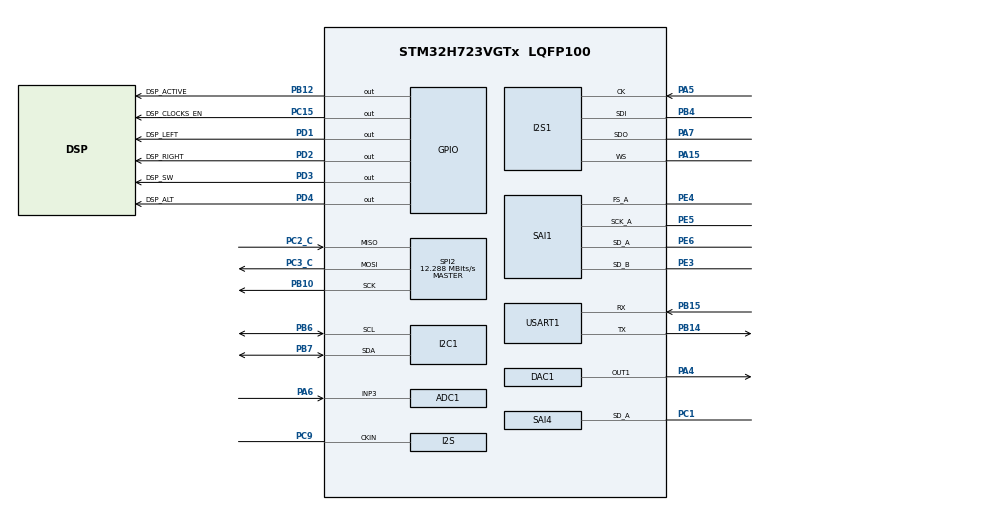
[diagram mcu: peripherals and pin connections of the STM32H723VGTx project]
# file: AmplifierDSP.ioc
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ADC1.Channel-1\#ChannelRegularConversion=ADC_CHANNEL_3
ADC1.NbrOfConversionFlag=1
ADC1.OffsetNumber-1\#ChannelRegularConversion=ADC_OFFSET_NONE
ADC1.OffsetSignedSaturation-1\#ChannelRegularConversion=DISABLE
ADC1.Rank-1\#ChannelRegularConversion=1
ADC1.SamplingTime-1\#ChannelRegularConversion=ADC_SAMPLETIME_1CYCLE_5
ADC1.master=1
Bdma.Request0=SAI4_A
Bdma.RequestsNb=1
Bdma.SAI4_A.0.Direction=DMA_MEMORY_TO_PERIPH
Bdma.SAI4_A.0.EventEnable=DISABLE
Bdma.SAI4_A.0.Instance=BDMA_Channel0
Bdma.SAI4_A.0.MemDataAlignment=DMA_MDATAALIGN_WORD
Bdma.SAI4_A.0.MemInc=DMA_MINC_ENABLE
Bdma.SAI4_A.0.Mode=DMA_NORMAL
Bdma.SAI4_A.0.PeriphDataAlignment=DMA_PDATAALIGN_WORD
Bdma.SAI4_A.0.PeriphInc=DMA_PINC_DISABLE
Bdma.SAI4_A.0.Polarity=HAL_DMAMUX_REQ_GEN_RISING
Bdma.SAI4_A.0.Priority=DMA_PRIORITY_VERY_HIGH
Bdma.SAI4_A.0.RequestNumber=1
Bdma.SAI4_A.0.SignalID=NONE
Bdma.SAI4_A.0.SyncEnable=DISABLE
Bdma.SAI4_A.0.SyncPolarity=HAL_DMAMUX_SYNC_NO_EVENT
Bdma.SAI4_A.0.SyncRequestNumber=1
Bdma.SAI4_A.0.SyncSignalID=NONE
CORTEX_M7.default_mode_Activation=1
DAC1.DAC_Channel-DAC_OUT1=DAC_CHANNEL_1
Dma.Request0=SPI1_RX
Dma.Request1=SPI1_TX
Dma.Request2=SAI1_A
Dma.Request3=SAI1_B
Dma.SAI1_A.2.Direction=DMA_MEMORY_TO_PERIPH
Dma.SAI1_A.2.EventEnable=DISABLE
Dma.SAI1_A.2.FIFOMode=DMA_FIFOMODE_DISABLE
Dma.SAI1_A.2.Instance=DMA1_Stream2
Dma.SAI1_A.2.MemDataAlignment=DMA_MDATAALIGN_WORD
Dma.SAI1_A.2.MemInc=DMA_MINC_ENABLE
Dma.SAI1_A.2.Mode=DMA_CIRCULAR
Dma.SAI1_A.2.PeriphDataAlignment=DMA_PDATAALIGN_WORD
Dma.SAI1_A.2.PeriphInc=DMA_PINC_DISABLE
Dma.SAI1_A.2.Polarity=HAL_DMAMUX_REQ_GEN_RISING
Dma.SAI1_A.2.Priority=DMA_PRIORITY_VERY_HIGH
Dma.SAI1_A.2.RequestNumber=1
Dma.SAI1_A.2.SignalID=NONE
Dma.SAI1_A.2.SyncEnable=DISABLE
Dma.SAI1_A.2.SyncPolarity=HAL_DMAMUX_SYNC_NO_EVENT
Dma.SAI1_A.2.SyncRequestNumber=1
Dma.SAI1_A.2.SyncSignalID=NONE
Dma.SAI1_B.3.Direction=DMA_MEMORY_TO_PERIPH
Dma.SAI1_B.3.EventEnable=DISABLE
Dma.SAI1_B.3.FIFOMode=DMA_FIFOMODE_DISABLE
Dma.SAI1_B.3.Instance=DMA1_Stream3
Dma.SAI1_B.3.MemDataAlignment=DMA_MDATAALIGN_WORD
Dma.SAI1_B.3.MemInc=DMA_MINC_ENABLE
Dma.SAI1_B.3.Mode=DMA_NORMAL
Dma.SAI1_B.3.PeriphDataAlignment=DMA_PDATAALIGN_WORD
Dma.SAI1_B.3.PeriphInc=DMA_PINC_DISABLE
Dma.SAI1_B.3.Polarity=HAL_DMAMUX_REQ_GEN_RISING
Dma.SAI1_B.3.Priority=DMA_PRIORITY_VERY_HIGH
Dma.SAI1_B.3.RequestNumber=1
Dma.SAI1_B.3.SignalID=NONE
Dma.SAI1_B.3.SyncEnable=DISABLE
Dma.SAI1_B.3.SyncPolarity=HAL_DMAMUX_SYNC_NO_EVENT
Dma.SAI1_B.3.SyncRequestNumber=1
Dma.SAI1_B.3.SyncSignalID=NONE
Dma.SPI1_RX.0.Direction=DMA_PERIPH_TO_MEMORY
Dma.SPI1_RX.0.EventEnable=DISABLE
Dma.SPI1_RX.0.FIFOMode=DMA_FIFOMODE_DISABLE
Dma.SPI1_RX.0.Instance=DMA1_Stream0
Dma.SPI1_RX.0.MemDataAlignment=DMA_MDATAALIGN_WORD
Dma.SPI1_RX.0.MemInc=DMA_MINC_ENABLE
Dma.SPI1_RX.0.Mode=DMA_CIRCULAR
Dma.SPI1_RX.0.PeriphDataAlignment=DMA_PDATAALIGN_WORD
Dma.SPI1_RX.0.PeriphInc=DMA_PINC_DISABLE
Dma.SPI1_RX.0.Polarity=HAL_DMAMUX_REQ_GEN_RISING
Dma.SPI1_RX.0.Priority=DMA_PRIORITY_VERY_HIGH
Dma.SPI1_RX.0.RequestNumber=1
Dma.SPI1_RX.0.SignalID=NONE
Dma.SPI1_RX.0.SyncEnable=DISABLE
Dma.SPI1_RX.0.SyncPolarity=HAL_DMAMUX_SYNC_NO_EVENT
Dma.SPI1_RX.0.SyncRequestNumber=1
Dma.SPI1_RX.0.SyncSignalID=NONE
Dma.SPI1_TX.1.Direction=DMA_MEMORY_TO_PERIPH
Dma.SPI1_TX.1.EventEnable=DISABLE
Dma.SPI1_TX.1.FIFOMode=DMA_FIFOMODE_DISABLE
Dma.SPI1_TX.1.Instance=DMA1_Stream1
Dma.SPI1_TX.1.MemDataAlignment=DMA_MDATAALIGN_WORD
Dma.SPI1_TX.1.MemInc=DMA_MINC_ENABLE
Dma.SPI1_TX.1.Mode=DMA_CIRCULAR
Dma.SPI1_TX.1.PeriphDataAlignment=DMA_PDATAALIGN_WORD
Dma.SPI1_TX.1.PeriphInc=DMA_PINC_DISABLE
Dma.SPI1_TX.1.Polarity=HAL_DMAMUX_REQ_GEN_RISING
Dma.SPI1_TX.1.Priority=DMA_PRIORITY_VERY_HIGH
Dma.SPI1_TX.1.RequestNumber=1
Dma.SPI1_TX.1.SignalID=NONE
Dma.SPI1_TX.1.SyncEnable=DISABLE
Dma.SPI1_TX.1.SyncPolarity=HAL_DMAMUX_SYNC_NO_EVENT
Dma.SPI1_TX.1.SyncRequestNumber=1
Dma.SPI1_TX.1.SyncSignalID=NONE
FREERTOS.Tasks01=mainThread,24,128,startMainThread,Default,NULL,Dynamic,NULL,NULL;audioThread,32,128,startAudioThread,Default,NULL,Dynamic,NULL,NULL
FREERTOS.configENABLE_FPU=1
FREERTOS.configUSE_NEWLIB_REENTRANT=1
I2C1.OwnAddress=50
I2C1.Timing=0x20A0A3F6
I2S1.AudioFreq=I2S_AUDIOFREQ_48K
I2S1.DataFormat=I2S_DATAFORMAT_24B
I2S1.ErrorAudioFreq=0.0 %
I2S1.Instance=SPI$Index
I2S1.RealAudioFreq=48.0 KHz
Mcu.Family=STM32H7
Mcu.Name=STM32H723VGTx
Mcu.Package=LQFP100
NVIC.BDMA_Channel0_IRQn=true\:5\:0\:false\:false\:true\:true\:false\:true\:true
NVIC.DMA1_Stream0_IRQn=true\:5\:0\:false\:false\:true\:true\:false\:true\:true
NVIC.DMA1_Stream1_IRQn=true\:5\:0\:false\:false\:true\:true\:false\:true\:true
NVIC.DMA1_Stream2_IRQn=true\:5\:0\:false\:false\:true\:true\:false\:true\:true
NVIC.DMA1_Stream3_IRQn=true\:5\:0\:false\:false\:true\:true\:false\:true\:true
NVIC.I2C1_ER_IRQn=true\:5\:0\:false\:false\:true\:true\:true\:true\:true
NVIC.I2C1_EV_IRQn=true\:5\:0\:false\:false\:true\:true\:true\:true\:true
NVIC.PriorityGroup=NVIC_PRIORITYGROUP_4
PA13(JTMS/SWDIO).Mode=Trace_Asynchronous_SW
PA13(JTMS/SWDIO).Signal=DEBUG_JTMS-SWDIO
PA14(JTCK/SWCLK).Mode=Trace_Asynchronous_SW
PA14(JTCK/SWCLK).Signal=DEBUG_JTCK-SWCLK
PA15(JTDI).Mode=Full_Duplex_Slave
PA15(JTDI).Signal=I2S1_WS
PA4.Signal=COMP_DAC11_group
PA5.Mode=Full_Duplex_Slave
PA5.Signal=I2S1_CK
PA6.Signal=ADCx_INP3
PA7.Mode=Full_Duplex_Slave
PA7.Signal=I2S1_SDO
PB10.Mode=Full_Duplex_Master
PB10.Signal=SPI2_SCK
PB12.GPIO_Label=DSP_ACTIVE
PB12.GPIO_PuPd=GPIO_PULLDOWN
PB12.Signal=GPIO_Output
PB14.Mode=Asynchronous
PB14.Signal=USART1_TX
PB15.Mode=Asynchronous
PB15.Signal=USART1_RX
PB3(JTDO/TRACESWO).Mode=Trace_Asynchronous_SW
PB3(JTDO/TRACESWO).Signal=DEBUG_JTDO-SWO
PB4(NJTRST).Mode=Full_Duplex_Slave
PB4(NJTRST).Signal=I2S1_SDI
PB6.Mode=I2C
PB6.Signal=I2C1_SCL
PB7.Mode=I2C
PB7.Signal=I2C1_SDA
PC1.Mode=SAI_A_SyncSlave
PC1.Signal=SAI4_SD_A
PC15-OSC32_OUT.GPIO_Label=DSP_CLOCKS_EN
PC15-OSC32_OUT.GPIO_PuPd=GPIO_PULLDOWN
PC15-OSC32_OUT.Signal=GPIO_Output
PC2_C.Mode=Full_Duplex_Master
PC2_C.Signal=SPI2_MISO
PC3_C.Mode=Full_Duplex_Master
PC3_C.Signal=SPI2_MOSI
PC9.Mode=Audio_ClockIn
PC9.Signal=I2S_CKIN
PD1.GPIO_Label=DSP_LEFT
PD1.GPIO_PuPd=GPIO_PULLDOWN
PD1.Signal=GPIO_Output
PD2.GPIO_Label=DSP_RIGHT
PD2.GPIO_PuPd=GPIO_PULLDOWN
PD2.Signal=GPIO_Output
PD3.GPIO_Label=DSP_SW
PD3.GPIO_PuPd=GPIO_PULLDOWN
PD3.Signal=GPIO_Output
PD4.GPIO_Label=DSP_ALT
PD4.GPIO_PuPd=GPIO_PULLDOWN
PD4.Signal=GPIO_Output
PE3.Mode=SAI_B_SyncSlave
PE3.Signal=SAI1_SD_B
PE4.Mode=SAI_A_AsyncSlave
PE4.Signal=SAI1_FS_A
PE5.Mode=SAI_A_AsyncSlave
PE5.Signal=SAI1_SCK_A
PE6.Mode=SAI_A_AsyncSlave
PE6.Signal=SAI1_SD_A
ProjectManager.HeapSize=0x200
ProjectManager.StackSize=0x400
ProjectManager.TargetToolchain=STM32CubeIDE
RCC.ADCFreq_Value=129000000
RCC.APB1Freq_Value=125000000
RCC.APB2Freq_Value=125000000
RCC.APB3Freq_Value=125000000
RCC.APB4Freq_Value=125000000
RCC.CortexFreq_Value=500000000
RCC.D1PPRE=RCC_APB3_DIV2
RCC.D2PPRE1=RCC_APB1_DIV2
RCC.D2PPRE2=RCC_APB2_DIV2
RCC.D3PPRE=RCC_APB4_DIV2
RCC.DIVM1=4
RCC.DIVN1=31
RCC.DIVP1=1
RCC.DIVQ1=4
RCC.EXTERNAL_CLOCK_VALUE=24576000
RCC.HCLKFreq_Value=250000000
RCC.HPRE=RCC_HCLK_DIV2
RCC.PLL2FRACN=0
RCC.PLL3FRACN=0
RCC.PLLFRACN=2048
RCC.SAI1CLockSelection=RCC_SAI1CLKSOURCE_PIN
RCC.SAI4ACLockSelection=RCC_SAI4ACLKSOURCE_PIN
RCC.SAI4BCLockSelection=RCC_SAI4BCLKSOURCE_PIN
RCC.SPI123CLockSelection=RCC_SPI123CLKSOURCE_PIN
RCC.SYSCLKFreq_VALUE=500000000
RCC.SYSCLKSource=RCC_SYSCLKSOURCE_PLLCLK
RCC.USBFreq_Value=125000000
SAI1.AudioMode-SAI_A_AsyncSlave=SAI_MODESLAVE_TX
SAI1.AudioMode-SAI_B_SyncSlave=SAI_MODESLAVE_TX
SAI1.BasicDataSize-SAI_A_AsyncSlave=SAI_PROTOCOL_DATASIZE_24BIT
SAI1.BasicDataSize-SAI_B_SyncSlave=SAI_PROTOCOL_DATASIZE_24BIT
SAI1.InitProtocol-SAI_A_AsyncSlave=Enable
SAI1.InitProtocol-SAI_B_SyncSlave=Enable
SAI1.Instance-SAI_A_AsyncSlave=SAI$Index_Block_A
SAI1.Instance-SAI_B_SyncSlave=SAI$Index_Block_B
SAI1.VirtualMode-SAI_A_AsyncSlave=VM_SLAVE
SAI1.VirtualMode-SAI_B_SyncSlave=VM_SLAVE
SAI1.VirtualProtocol-SAI_A_BASIC=VM_BASIC_PROTOCOL
SAI1.VirtualProtocol-SAI_B_BASIC=VM_BASIC_PROTOCOL
SAI4.AudioMode-SAI_A_SyncSlave=SAI_MODESLAVE_TX
SAI4.BasicDataSize-SAI_A_SyncSlave=SAI_PROTOCOL_DATASIZE_24BIT
SAI4.InitProtocol-SAI_A_SyncSlave=Enable
SAI4.Instance-SAI_A_SyncSlave=SAI$Index_Block_A
SAI4.VirtualMode-SAI_A_SyncSlave=VM_SLAVE
SAI4.VirtualProtocol-SAI_A_BASIC=VM_BASIC_PROTOCOL
SH.ADCx_INP3.0=ADC1_INP3,IN3-Single-Ended
SH.COMP_DAC11_group.0=DAC1_OUT1,DAC_OUT1
SPI2.CalculateBaudRate=12.288 MBits/s
SPI2.Direction=SPI_DIRECTION_2LINES
SPI2.Mode=SPI_MODE_MASTER
SPI2.VirtualType=VM_MASTER
USART1.VirtualMode-Asynchronous=VM_ASYNC
VP_FREERTOS_VS_CMSIS_V2.Mode=CMSIS_V2
VP_MEMORYMAP_VS_MEMORYMAP.Mode=CurAppReg
VP_SAI1_VP_$IpInstance_SAIA_SAI_BASIC.Mode=SAI_A_BASIC
VP_SAI1_VP_$IpInstance_SAIB_SAI_BASIC.Mode=SAI_B_BASIC
VP_SAI4_VP_$IpInstance_SAIA_SAI_BASIC.Mode=SAI_A_BASIC
board=custom

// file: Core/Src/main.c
/* USER CODE BEGIN Header */
/**
  ******************************************************************************
  * @file           : main.c
  * @brief          : Main program body
  ******************************************************************************
  * @attention
  *
  * Copyright (c) 2024 STMicroelectronics.
  * All rights reserved.
  *
  * This software is licensed under terms that can be found in the LICENSE file
  * in the root directory of this software component.
  * If no LICENSE file comes with this software, it is provided AS-IS.
  *
  ******************************************************************************
  */
/* USER CODE END Header */
#include "main.h"
#include "cmsis_os.h"

/* USER CODE BEGIN Includes */

#include <stdlib.h>
#include "arm_math.h"

/* USER CODE END Includes */

ADC_HandleTypeDef hadc1;

DAC_HandleTypeDef hdac1;

I2C_HandleTypeDef hi2c1;

I2S_HandleTypeDef hi2s1;
DMA_HandleTypeDef hdma_spi1_rx;
DMA_HandleTypeDef hdma_spi1_tx;

SAI_HandleTypeDef hsai_BlockA1;
SAI_HandleTypeDef hsai_BlockB1;
SAI_HandleTypeDef hsai_BlockA4;
DMA_HandleTypeDef hdma_sai1_a;
DMA_HandleTypeDef hdma_sai1_b;
DMA_HandleTypeDef hdma_sai4_a;

SPI_HandleTypeDef hspi2;

UART_HandleTypeDef huart1;

/* Definitions for mainThread */
osThreadId_t mainThreadHandle;
const osThreadAttr_t mainThread_attributes = {
  .name = "mainThread",
  .stack_size = 128 * 4,
  .priority = (osPriority_t) osPriorityNormal,
};
/* Definitions for audioThread */
osThreadId_t audioThreadHandle;
const osThreadAttr_t audioThread_attributes = {
  .name = "audioThread",
  .stack_size = 128 * 4,
  .priority = (osPriority_t) osPriorityAboveNormal,
};

void SystemClock_Config(void);
static void MPU_Config(void);
static void MX_GPIO_Init(void);
static void MX_DMA_Init(void);
static void MX_BDMA_Init(void);
static void MX_I2S1_Init(void);
static void MX_ADC1_Init(void);
static void MX_DAC1_Init(void);
static void MX_I2C1_Init(void);
static void MX_SPI2_Init(void);
static void MX_USART1_UART_Init(void);
static void MX_SAI4_Init(void);
static void MX_SAI1_Init(void);
void startMainThread(void *argument);
void startAudioThread(void *argument);

/* USER CODE BEGIN 0 */

#define FFT_Length  1024
float32_t FFT_Input_Q15_f[50];
float32_t aFFT_Input_Q15[50];

/* USER CODE END 0 */

int main(void)
{

  /* MPU Configuration--------------------------------------------------------*/
  MPU_Config();

  /* MCU Configuration--------------------------------------------------------*/

  /* Reset of all peripherals, Initializes the Flash interface and the Systick. */
  HAL_Init();

  /* Configure the system clock */
  SystemClock_Config();

  /* Initialize all configured peripherals */
  MX_GPIO_Init();
  MX_DMA_Init();
  MX_BDMA_Init();
  MX_I2S1_Init();
  MX_ADC1_Init();
  MX_DAC1_Init();
  MX_I2C1_Init();
  MX_SPI2_Init();
  MX_USART1_UART_Init();
  MX_SAI4_Init();
  MX_SAI1_Init();

  /* Init scheduler */
  osKernelInitialize();

  /* Create the thread(s) */
  /* creation of mainThread */
  mainThreadHandle = osThreadNew(startMainThread, NULL, &mainThread_attributes);

  /* creation of audioThread */
  audioThreadHandle = osThreadNew(startAudioThread, NULL, &audioThread_attributes);

  /* Start scheduler */
  osKernelStart();

  /* We should never get here as control is now taken by the scheduler */

  /* Infinite loop */
  while (1)
  {

    /* USER CODE BEGIN 3 */

	  HAL_GPIO_WritePin( DSP_ACTIVE_GPIO_Port, DSP_ACTIVE_Pin, GPIO_PIN_SET );
	  HAL_GPIO_WritePin( GPIOD, DSP_LEFT_Pin|DSP_RIGHT_Pin|DSP_SW_Pin|DSP_ALT_Pin, GPIO_PIN_SET );

	  HAL_Delay( 500 );

	  HAL_GPIO_WritePin( GPIOD, DSP_LEFT_Pin|DSP_RIGHT_Pin|DSP_SW_Pin|DSP_ALT_Pin, GPIO_PIN_RESET );

	  HAL_Delay( 500 );

	  arm_float_to_q15((float32_t *)&FFT_Input_Q15_f[0], (q15_t *)&aFFT_Input_Q15[0], FFT_Length*2);
  }
  /* USER CODE END 3 */
}

void SystemClock_Config(void)
{
  RCC_OscInitTypeDef RCC_OscInitStruct = {0};
  RCC_ClkInitTypeDef RCC_ClkInitStruct = {0};

  /** Supply configuration update enable
  */
  HAL_PWREx_ConfigSupply(PWR_LDO_SUPPLY);

  /** Configure the main internal regulator output voltage
  */
  __HAL_PWR_VOLTAGESCALING_CONFIG(PWR_REGULATOR_VOLTAGE_SCALE0);

  while(!__HAL_PWR_GET_FLAG(PWR_FLAG_VOSRDY)) {}

  /** Initializes the RCC Oscillators according to the specified parameters
  * in the RCC_OscInitTypeDef structure.
  */
  RCC_OscInitStruct.OscillatorType = RCC_OSCILLATORTYPE_HSI;
  RCC_OscInitStruct.HSIState = RCC_HSI_DIV1;
  RCC_OscInitStruct.HSICalibrationValue = 64;
  RCC_OscInitStruct.PLL.PLLState = RCC_PLL_ON;
  RCC_OscInitStruct.PLL.PLLSource = RCC_PLLSOURCE_HSI;
  RCC_OscInitStruct.PLL.PLLM = 4;
  RCC_OscInitStruct.PLL.PLLN = 31;
  RCC_OscInitStruct.PLL.PLLP = 1;
  RCC_OscInitStruct.PLL.PLLQ = 4;
  RCC_OscInitStruct.PLL.PLLR = 2;
  RCC_OscInitStruct.PLL.PLLRGE = RCC_PLL1VCIRANGE_3;
  RCC_OscInitStruct.PLL.PLLVCOSEL = RCC_PLL1VCOWIDE;
  RCC_OscInitStruct.PLL.PLLFRACN = 2048;
  if (HAL_RCC_OscConfig(&RCC_OscInitStruct) != HAL_OK)
  {
    Error_Handler();
  }

  /** Initializes the CPU, AHB and APB buses clocks
  */
  RCC_ClkInitStruct.ClockType = RCC_CLOCKTYPE_HCLK|RCC_CLOCKTYPE_SYSCLK
                              |RCC_CLOCKTYPE_PCLK1|RCC_CLOCKTYPE_PCLK2
                              |RCC_CLOCKTYPE_D3PCLK1|RCC_CLOCKTYPE_D1PCLK1;
  RCC_ClkInitStruct.SYSCLKSource = RCC_SYSCLKSOURCE_PLLCLK;
  RCC_ClkInitStruct.SYSCLKDivider = RCC_SYSCLK_DIV1;
  RCC_ClkInitStruct.AHBCLKDivider = RCC_HCLK_DIV2;
  RCC_ClkInitStruct.APB3CLKDivider = RCC_APB3_DIV2;
  RCC_ClkInitStruct.APB1CLKDivider = RCC_APB1_DIV2;
  RCC_ClkInitStruct.APB2CLKDivider = RCC_APB2_DIV2;
  RCC_ClkInitStruct.APB4CLKDivider = RCC_APB4_DIV2;

  if (HAL_RCC_ClockConfig(&RCC_ClkInitStruct, FLASH_LATENCY_3) != HAL_OK)
  {
    Error_Handler();
  }
}

static void MX_ADC1_Init(void)
{

  ADC_MultiModeTypeDef multimode = {0};
  ADC_ChannelConfTypeDef sConfig = {0};

  /** Common config
  */
  hadc1.Instance = ADC1;
  hadc1.Init.ClockPrescaler = ADC_CLOCK_ASYNC_DIV1;
  hadc1.Init.Resolution = ADC_RESOLUTION_16B;
  hadc1.Init.ScanConvMode = ADC_SCAN_DISABLE;
  hadc1.Init.EOCSelection = ADC_EOC_SINGLE_CONV;
  hadc1.Init.LowPowerAutoWait = DISABLE;
  hadc1.Init.ContinuousConvMode = DISABLE;
  hadc1.Init.NbrOfConversion = 1;
  hadc1.Init.DiscontinuousConvMode = DISABLE;
  hadc1.Init.ExternalTrigConv = ADC_SOFTWARE_START;
  hadc1.Init.ExternalTrigConvEdge = ADC_EXTERNALTRIGCONVEDGE_NONE;
  hadc1.Init.ConversionDataManagement = ADC_CONVERSIONDATA_DR;
  hadc1.Init.Overrun = ADC_OVR_DATA_PRESERVED;
  hadc1.Init.LeftBitShift = ADC_LEFTBITSHIFT_NONE;
  hadc1.Init.OversamplingMode = DISABLE;
  hadc1.Init.Oversampling.Ratio = 1;
  if (HAL_ADC_Init(&hadc1) != HAL_OK)
  {
    Error_Handler();
  }

  /** Configure the ADC multi-mode
  */
  multimode.Mode = ADC_MODE_INDEPENDENT;
  if (HAL_ADCEx_MultiModeConfigChannel(&hadc1, &multimode) != HAL_OK)
  {
    Error_Handler();
  }

  /** Configure Regular Channel
  */
  sConfig.Channel = ADC_CHANNEL_3;
  sConfig.Rank = ADC_REGULAR_RANK_1;
  sConfig.SamplingTime = ADC_SAMPLETIME_1CYCLE_5;
  sConfig.SingleDiff = ADC_SINGLE_ENDED;
  sConfig.OffsetNumber = ADC_OFFSET_NONE;
  sConfig.Offset = 0;
  sConfig.OffsetSignedSaturation = DISABLE;
  if (HAL_ADC_ConfigChannel(&hadc1, &sConfig) != HAL_OK)
  {
    Error_Handler();
  }

}

static void MX_DAC1_Init(void)
{

  DAC_ChannelConfTypeDef sConfig = {0};

  /** DAC Initialization
  */
  hdac1.Instance = DAC1;
  if (HAL_DAC_Init(&hdac1) != HAL_OK)
  {
    Error_Handler();
  }

  /** DAC channel OUT1 config
  */
  sConfig.DAC_SampleAndHold = DAC_SAMPLEANDHOLD_DISABLE;
  sConfig.DAC_Trigger = DAC_TRIGGER_NONE;
  sConfig.DAC_OutputBuffer = DAC_OUTPUTBUFFER_ENABLE;
  sConfig.DAC_ConnectOnChipPeripheral = DAC_CHIPCONNECT_DISABLE;
  sConfig.DAC_UserTrimming = DAC_TRIMMING_FACTORY;
  if (HAL_DAC_ConfigChannel(&hdac1, &sConfig, DAC_CHANNEL_1) != HAL_OK)
  {
    Error_Handler();
  }

}

static void MX_I2C1_Init(void)
{

  hi2c1.Instance = I2C1;
  hi2c1.Init.Timing = 0x20A0A3F6;
  hi2c1.Init.OwnAddress1 = 100;
  hi2c1.Init.AddressingMode = I2C_ADDRESSINGMODE_7BIT;
  hi2c1.Init.DualAddressMode = I2C_DUALADDRESS_DISABLE;
  hi2c1.Init.OwnAddress2 = 0;
  hi2c1.Init.OwnAddress2Masks = I2C_OA2_NOMASK;
  hi2c1.Init.GeneralCallMode = I2C_GENERALCALL_DISABLE;
  hi2c1.Init.NoStretchMode = I2C_NOSTRETCH_DISABLE;
  if (HAL_I2C_Init(&hi2c1) != HAL_OK)
  {
    Error_Handler();
  }

  /** Configure Analogue filter
  */
  if (HAL_I2CEx_ConfigAnalogFilter(&hi2c1, I2C_ANALOGFILTER_ENABLE) != HAL_OK)
  {
    Error_Handler();
  }

  /** Configure Digital filter
  */
  if (HAL_I2CEx_ConfigDigitalFilter(&hi2c1, 0) != HAL_OK)
  {
    Error_Handler();
  }
  /* USER CODE BEGIN I2C1_Init 2 */

  HAL_I2C_EnableListen_IT(&hi2c1);

  /* USER CODE END I2C1_Init 2 */

}

static void MX_I2S1_Init(void)
{

  hi2s1.Instance = SPI1;
  hi2s1.Init.Mode = I2S_MODE_SLAVE_FULLDUPLEX;
  hi2s1.Init.Standard = I2S_STANDARD_PHILIPS;
  hi2s1.Init.DataFormat = I2S_DATAFORMAT_24B;
  hi2s1.Init.MCLKOutput = I2S_MCLKOUTPUT_DISABLE;
  hi2s1.Init.AudioFreq = I2S_AUDIOFREQ_48K;
  hi2s1.Init.CPOL = I2S_CPOL_LOW;
  hi2s1.Init.FirstBit = I2S_FIRSTBIT_MSB;
  hi2s1.Init.WSInversion = I2S_WS_INVERSION_DISABLE;
  hi2s1.Init.Data24BitAlignment = I2S_DATA_24BIT_ALIGNMENT_RIGHT;
  hi2s1.Init.MasterKeepIOState = I2S_MASTER_KEEP_IO_STATE_DISABLE;
  if (HAL_I2S_Init(&hi2s1) != HAL_OK)
  {
    Error_Handler();
  }

}

static void MX_SAI1_Init(void)
{

  hsai_BlockA1.Instance = SAI1_Block_A;
  hsai_BlockA1.Init.AudioMode = SAI_MODESLAVE_TX;
  hsai_BlockA1.Init.Synchro = SAI_ASYNCHRONOUS;
  hsai_BlockA1.Init.OutputDrive = SAI_OUTPUTDRIVE_DISABLE;
  hsai_BlockA1.Init.FIFOThreshold = SAI_FIFOTHRESHOLD_EMPTY;
  hsai_BlockA1.Init.SynchroExt = SAI_SYNCEXT_DISABLE;
  hsai_BlockA1.Init.MonoStereoMode = SAI_STEREOMODE;
  hsai_BlockA1.Init.CompandingMode = SAI_NOCOMPANDING;
  hsai_BlockA1.Init.TriState = SAI_OUTPUT_NOTRELEASED;
  if (HAL_SAI_InitProtocol(&hsai_BlockA1, SAI_I2S_STANDARD, SAI_PROTOCOL_DATASIZE_24BIT, 2) != HAL_OK)
  {
    Error_Handler();
  }
  hsai_BlockB1.Instance = SAI1_Block_B;
  hsai_BlockB1.Init.AudioMode = SAI_MODESLAVE_TX;
  hsai_BlockB1.Init.Synchro = SAI_SYNCHRONOUS;
  hsai_BlockB1.Init.OutputDrive = SAI_OUTPUTDRIVE_DISABLE;
  hsai_BlockB1.Init.FIFOThreshold = SAI_FIFOTHRESHOLD_EMPTY;
  hsai_BlockB1.Init.SynchroExt = SAI_SYNCEXT_DISABLE;
  hsai_BlockB1.Init.MonoStereoMode = SAI_STEREOMODE;
  hsai_BlockB1.Init.CompandingMode = SAI_NOCOMPANDING;
  hsai_BlockB1.Init.TriState = SAI_OUTPUT_NOTRELEASED;
  if (HAL_SAI_InitProtocol(&hsai_BlockB1, SAI_I2S_STANDARD, SAI_PROTOCOL_DATASIZE_24BIT, 2) != HAL_OK)
  {
    Error_Handler();
  }

}

static void MX_SAI4_Init(void)
{

  hsai_BlockA4.Instance = SAI4_Block_A;
  hsai_BlockA4.Init.AudioMode = SAI_MODESLAVE_TX;
  hsai_BlockA4.Init.Synchro = SAI_SYNCHRONOUS;
  hsai_BlockA4.Init.OutputDrive = SAI_OUTPUTDRIVE_DISABLE;
  hsai_BlockA4.Init.FIFOThreshold = SAI_FIFOTHRESHOLD_EMPTY;
  hsai_BlockA4.Init.MonoStereoMode = SAI_STEREOMODE;
  hsai_BlockA4.Init.CompandingMode = SAI_NOCOMPANDING;
  hsai_BlockA4.Init.TriState = SAI_OUTPUT_NOTRELEASED;
  if (HAL_SAI_InitProtocol(&hsai_BlockA4, SAI_I2S_STANDARD, SAI_PROTOCOL_DATASIZE_24BIT, 2) != HAL_OK)
  {
    Error_Handler();
  }

}

static void MX_SPI2_Init(void)
{

  /* SPI2 parameter configuration*/
  hspi2.Instance = SPI2;
  hspi2.Init.Mode = SPI_MODE_MASTER;
  hspi2.Init.Direction = SPI_DIRECTION_2LINES;
  hspi2.Init.DataSize = SPI_DATASIZE_4BIT;
  hspi2.Init.CLKPolarity = SPI_POLARITY_LOW;
  hspi2.Init.CLKPhase = SPI_PHASE_1EDGE;
  hspi2.Init.NSS = SPI_NSS_SOFT;
  hspi2.Init.BaudRatePrescaler = SPI_BAUDRATEPRESCALER_2;
  hspi2.Init.FirstBit = SPI_FIRSTBIT_MSB;
  hspi2.Init.TIMode = SPI_TIMODE_DISABLE;
  hspi2.Init.CRCCalculation = SPI_CRCCALCULATION_DISABLE;
  hspi2.Init.CRCPolynomial = 0x0;
  hspi2.Init.NSSPMode = SPI_NSS_PULSE_ENABLE;
  hspi2.Init.NSSPolarity = SPI_NSS_POLARITY_LOW;
  hspi2.Init.FifoThreshold = SPI_FIFO_THRESHOLD_01DATA;
  hspi2.Init.TxCRCInitializationPattern = SPI_CRC_INITIALIZATION_ALL_ZERO_PATTERN;
  hspi2.Init.RxCRCInitializationPattern = SPI_CRC_INITIALIZATION_ALL_ZERO_PATTERN;
  hspi2.Init.MasterSSIdleness = SPI_MASTER_SS_IDLENESS_00CYCLE;
  hspi2.Init.MasterInterDataIdleness = SPI_MASTER_INTERDATA_IDLENESS_00CYCLE;
  hspi2.Init.MasterReceiverAutoSusp = SPI_MASTER_RX_AUTOSUSP_DISABLE;
  hspi2.Init.MasterKeepIOState = SPI_MASTER_KEEP_IO_STATE_DISABLE;
  hspi2.Init.IOSwap = SPI_IO_SWAP_DISABLE;
  if (HAL_SPI_Init(&hspi2) != HAL_OK)
  {
    Error_Handler();
  }

}

static void MX_USART1_UART_Init(void)
{

  huart1.Instance = USART1;
  huart1.Init.BaudRate = 115200;
  huart1.Init.WordLength = UART_WORDLENGTH_8B;
  huart1.Init.StopBits = UART_STOPBITS_1;
  huart1.Init.Parity = UART_PARITY_NONE;
  huart1.Init.Mode = UART_MODE_TX_RX;
  huart1.Init.HwFlowCtl = UART_HWCONTROL_NONE;
  huart1.Init.OverSampling = UART_OVERSAMPLING_16;
  huart1.Init.OneBitSampling = UART_ONE_BIT_SAMPLE_DISABLE;
  huart1.Init.ClockPrescaler = UART_PRESCALER_DIV1;
  huart1.AdvancedInit.AdvFeatureInit = UART_ADVFEATURE_NO_INIT;
  if (HAL_UART_Init(&huart1) != HAL_OK)
  {
    Error_Handler();
  }
  if (HAL_UARTEx_SetTxFifoThreshold(&huart1, UART_TXFIFO_THRESHOLD_1_8) != HAL_OK)
  {
    Error_Handler();
  }
  if (HAL_UARTEx_SetRxFifoThreshold(&huart1, UART_RXFIFO_THRESHOLD_1_8) != HAL_OK)
  {
    Error_Handler();
  }
  if (HAL_UARTEx_DisableFifoMode(&huart1) != HAL_OK)
  {
    Error_Handler();
  }

}

static void MX_BDMA_Init(void)
{

  /* DMA controller clock enable */
  __HAL_RCC_BDMA_CLK_ENABLE();

  /* DMA interrupt init */
  /* BDMA_Channel0_IRQn interrupt configuration */
  HAL_NVIC_SetPriority(BDMA_Channel0_IRQn, 5, 0);
  HAL_NVIC_EnableIRQ(BDMA_Channel0_IRQn);

}

static void MX_DMA_Init(void)
{

  /* DMA controller clock enable */
  __HAL_RCC_DMA1_CLK_ENABLE();

  /* DMA interrupt init */
  /* DMA1_Stream0_IRQn interrupt configuration */
  HAL_NVIC_SetPriority(DMA1_Stream0_IRQn, 5, 0);
  HAL_NVIC_EnableIRQ(DMA1_Stream0_IRQn);
  /* DMA1_Stream1_IRQn interrupt configuration */
  HAL_NVIC_SetPriority(DMA1_Stream1_IRQn, 5, 0);
  HAL_NVIC_EnableIRQ(DMA1_Stream1_IRQn);
  /* DMA1_Stream2_IRQn interrupt configuration */
  HAL_NVIC_SetPriority(DMA1_Stream2_IRQn, 5, 0);
  HAL_NVIC_EnableIRQ(DMA1_Stream2_IRQn);
  /* DMA1_Stream3_IRQn interrupt configuration */
  HAL_NVIC_SetPriority(DMA1_Stream3_IRQn, 5, 0);
  HAL_NVIC_EnableIRQ(DMA1_Stream3_IRQn);

}

static void MX_GPIO_Init(void)
{
  GPIO_InitTypeDef GPIO_InitStruct = {0};

  /* GPIO Ports Clock Enable */
  __HAL_RCC_GPIOE_CLK_ENABLE();
  __HAL_RCC_GPIOC_CLK_ENABLE();
  __HAL_RCC_GPIOA_CLK_ENABLE();
  __HAL_RCC_GPIOB_CLK_ENABLE();
  __HAL_RCC_GPIOD_CLK_ENABLE();

  /*Configure GPIO pin Output Level */
  HAL_GPIO_WritePin(DSP_CLOCKS_EN_GPIO_Port, DSP_CLOCKS_EN_Pin, GPIO_PIN_RESET);

  /*Configure GPIO pin Output Level */
  HAL_GPIO_WritePin(DSP_ACTIVE_GPIO_Port, DSP_ACTIVE_Pin, GPIO_PIN_RESET);

  /*Configure GPIO pin Output Level */
  HAL_GPIO_WritePin(GPIOD, DSP_LEFT_Pin|DSP_RIGHT_Pin|DSP_SW_Pin|DSP_ALT_Pin, GPIO_PIN_RESET);

  /*Configure GPIO pin : DSP_CLOCKS_EN_Pin */
  GPIO_InitStruct.Pin = DSP_CLOCKS_EN_Pin;
  GPIO_InitStruct.Mode = GPIO_MODE_OUTPUT_PP;
  GPIO_InitStruct.Pull = GPIO_PULLDOWN;
  GPIO_InitStruct.Speed = GPIO_SPEED_FREQ_LOW;
  HAL_GPIO_Init(DSP_CLOCKS_EN_GPIO_Port, &GPIO_InitStruct);

  /*Configure GPIO pin : DSP_ACTIVE_Pin */
  GPIO_InitStruct.Pin = DSP_ACTIVE_Pin;
  GPIO_InitStruct.Mode = GPIO_MODE_OUTPUT_PP;
  GPIO_InitStruct.Pull = GPIO_PULLDOWN;
  GPIO_InitStruct.Speed = GPIO_SPEED_FREQ_LOW;
  HAL_GPIO_Init(DSP_ACTIVE_GPIO_Port, &GPIO_InitStruct);

  /*Configure GPIO pin : PC9 */
  GPIO_InitStruct.Pin = GPIO_PIN_9;
  GPIO_InitStruct.Mode = GPIO_MODE_AF_PP;
  GPIO_InitStruct.Pull = GPIO_NOPULL;
  GPIO_InitStruct.Speed = GPIO_SPEED_FREQ_LOW;
  GPIO_InitStruct.Alternate = GPIO_AF5_SPI1;
  HAL_GPIO_Init(GPIOC, &GPIO_InitStruct);

  /*Configure GPIO pins : DSP_LEFT_Pin DSP_RIGHT_Pin DSP_SW_Pin DSP_ALT_Pin */
  GPIO_InitStruct.Pin = DSP_LEFT_Pin|DSP_RIGHT_Pin|DSP_SW_Pin|DSP_ALT_Pin;
  GPIO_InitStruct.Mode = GPIO_MODE_OUTPUT_PP;
  GPIO_InitStruct.Pull = GPIO_PULLDOWN;
  GPIO_InitStruct.Speed = GPIO_SPEED_FREQ_LOW;
  HAL_GPIO_Init(GPIOD, &GPIO_InitStruct);

}

void startMainThread(void *argument)
{
  for(;;)
  {
    osDelay(1);
  }
}

void startAudioThread(void *argument)
{
  for(;;)
  {
    osDelay(1);
  }
}

 /* MPU Configuration */

void MPU_Config(void)
{
  MPU_Region_InitTypeDef MPU_InitStruct = {0};

  /* Disables the MPU */
  HAL_MPU_Disable();

  /** Initializes and configures the Region and the memory to be protected
  */
  MPU_InitStruct.Enable = MPU_REGION_ENABLE;
  MPU_InitStruct.Number = MPU_REGION_NUMBER0;
  MPU_InitStruct.BaseAddress = 0x0;
  MPU_InitStruct.Size = MPU_REGION_SIZE_4GB;
  MPU_InitStruct.SubRegionDisable = 0x87;
  MPU_InitStruct.TypeExtField = MPU_TEX_LEVEL0;
  MPU_InitStruct.AccessPermission = MPU_REGION_NO_ACCESS;
  MPU_InitStruct.DisableExec = MPU_INSTRUCTION_ACCESS_DISABLE;
  MPU_InitStruct.IsShareable = MPU_ACCESS_SHAREABLE;
  MPU_InitStruct.IsCacheable = MPU_ACCESS_NOT_CACHEABLE;
  MPU_InitStruct.IsBufferable = MPU_ACCESS_NOT_BUFFERABLE;

  HAL_MPU_ConfigRegion(&MPU_InitStruct);
  /* Enables the MPU */
  HAL_MPU_Enable(MPU_PRIVILEGED_DEFAULT);

}

void Error_Handler(void)
{
  __disable_irq();
  while (1)
  {
  }
}
